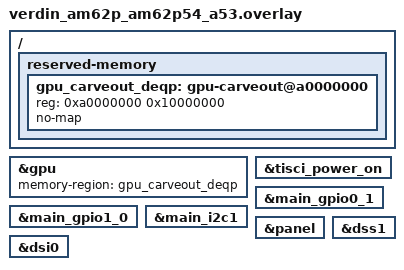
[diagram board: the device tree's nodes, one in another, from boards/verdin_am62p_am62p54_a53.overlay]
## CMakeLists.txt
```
# SPDX-License-Identifier: Apache-2.0
# SPDX-FileCopyrightText: 2026 Signal Slot, Inc.
# dEQP-GLES2 on Zephyr: the conformance suite as a Zephyr image, EGL/GLES from
# YakoGL, shaders from the in-process compiler. See README.md. One sample for
# every board: the Zephyr board (-b) picks the GPU and its board side, the
# board's files are in boards/. The STM32MP257F-DK's A35 adds the board
# layer's stm32mp2/app.conf (below). The Raspberry Pi 4 (V3D) adds src/v3d_board.c
# (the V3D's EGL default display and the result record, one screen the lead
# photographs), the mailbox framebuffer, the HDMI console and the
# bounded-lifetime watchdog of the rpi4 board layer.
#   -DDEQP_SRC=<CTS copy with cts-yakogl-zephyr.patch applied>
#   -DDEQP_BUILD=<its stage-1 build (static libraries)>
# tools/cts/cts-build-zephyr.sh makes both.
cmake_minimum_required(VERSION 3.20.0)
get_filename_component(PVR_REPO "${CMAKE_CURRENT_SOURCE_DIR}/../../.." ABSOLUTE)
include("${CMAKE_CURRENT_SOURCE_DIR}/../common/yakogl_dir.cmake")
# The STM32MP257F-DK's A35 takes the board layer's own board files, as
# gc_fence, gc_clear and gl_test do: app.conf here (the Vivante driver,
# OP-TEE's watchdog, no hold), app.overlay through
# boards/stm32mp257f_dk_stm32mp257fxx_a35.overlay, and dEQP's own needs in
# boards/stm32mp257f_dk_stm32mp257fxx_a35.conf.
if(BOARD MATCHES "^stm32mp257f_dk")
  set(EXTRA_CONF_FILE "${PVR_REPO}/zephyr/lib/board/stm32mp2/app.conf" ${EXTRA_CONF_FILE})
endif()
find_package(Zephyr REQUIRED HINTS $ENV{ZEPHYR_BASE})
project(deqp_zephyr)
set(PVR_SAMPLES "${CMAKE_CURRENT_SOURCE_DIR}/..")

foreach(v DEQP_SRC DEQP_BUILD)
  if(NOT ${v})
    message(FATAL_ERROR "deqp: set -D${v}=...")
  endif()
endforeach()

if(NOT CONFIG_YAKOGL_GPU_V3D)
  include("${PVR_SAMPLES}/common/sample.cmake")
endif()
# STM32MP257F-DK: the board layer (driver/zephyr/lib/board/stm32mp2) powers
# the GPU, arms OP-TEE's watchdog and ends the run (src/main.cpp:
# board_finish), with the yk-record line and PSCI SYSTEM_RESET into ST's Linux.
if(CONFIG_YAKOGL_STM32MP2 AND NOT CONFIG_YAKOGL_BOARD_STM32MP2)
  message(FATAL_ERROR "deqp: CONFIG_YAKOGL_BOARD is off (boards/stm32mp257f_dk_stm32mp257fxx_a35.conf turns it on)")
endif()

# Which dEQP package: gles2 (default) or gles3, against a stage 1 built with
# the same MODULE (tools/cts/cts-build-zephyr.sh). A gles3 image must let the
# library report ES 3.0: CONFIG_DEQP_REPORT_ES2=n and CONFIG_YAKOGL_REPORT_ES2=n
# (the latter is default y, so dropping the select alone still reports ES 2.0).
# dEQP-GLES3 on an ES 2.0 context is not supported.
if(NOT DEQP_MODULE)
  set(DEQP_MODULE gles2)
endif()
if(NOT DEQP_MODULE MATCHES "^gles[23]$")
  message(FATAL_ERROR "deqp: DEQP_MODULE must be gles2 or gles3, not ${DEQP_MODULE}")
endif()
if(DEQP_MODULE STREQUAL "gles3" AND CONFIG_DEQP_REPORT_ES2)
  message(FATAL_ERROR "deqp: DEQP_MODULE=gles3 needs CONFIG_DEQP_REPORT_ES2=n")
endif()
if(DEQP_MODULE STREQUAL "gles3" AND CONFIG_YAKOGL_REPORT_ES2)
  # DEQP_REPORT_ES2=n drops the select only; the library's default is y
  message(FATAL_ERROR "deqp: DEQP_MODULE=gles3 needs CONFIG_YAKOGL_REPORT_ES2=n too (the context must report ES 3.0)")
endif()
string(SUBSTRING "${DEQP_MODULE}" 4 1 _deqp_ver)

# the test data, embedded
set(_data_c "${CMAKE_CURRENT_BINARY_DIR}/deqp_data.c")
add_custom_command(OUTPUT "${_data_c}"
  COMMAND python3 "${CMAKE_CURRENT_SOURCE_DIR}/tools/embed_data.py"
          "${DEQP_BUILD}/modules/${DEQP_MODULE}/${DEQP_MODULE}" ${DEQP_MODULE} "${_data_c}"
  DEPENDS "${CMAKE_CURRENT_SOURCE_DIR}/tools/embed_data.py"
  COMMENT "embedding the dEQP ${DEQP_MODULE} test data")

target_sources(app PRIVATE src/main.cpp src/deqp_archive.cpp src/deqp_log.c src/deqp_stubs.c "${_data_c}"
  # the package registration lives in the executable's own entry file, not in
  # any library: without it the image has the tests but no package to run
  ${DEQP_SRC}/modules/${DEQP_MODULE}/tes${_deqp_ver}TestPackageEntry.cpp)
# The SNVS tally, on a board with yakogl_gc_board (the Verdin iMX8M Plus).
target_sources_ifdef(CONFIG_GC_COMMON_RESULT_SNVS app PRIVATE src/deqp_snvs.c)
target_include_directories(app PRIVATE src
  ${DEQP_SRC}/framework/common ${DEQP_SRC}/framework/qphelper
  ${DEQP_SRC}/framework/delibs/debase ${DEQP_SRC}/framework/delibs/decpp
  ${DEQP_SRC}/framework/delibs/depool ${DEQP_SRC}/framework/delibs/dethread
  ${DEQP_SRC}/framework/delibs/deutil ${DEQP_SRC}/framework/delibs/destream
  ${DEQP_SRC}/framework/referencerenderer ${DEQP_SRC}/framework/opengl
  ${DEQP_SRC}/framework/opengl/wrapper ${DEQP_SRC}/framework/egl
  ${DEQP_SRC}/framework/egl/wrapper ${DEQP_SRC}/modules/${DEQP_MODULE}
  ${DEQP_SRC}/modules/glshared ${DEQP_SRC}/framework/opengl/simplereference)
target_compile_definitions(app PRIVATE DE_OS=DE_OS_UNIX DE_CPU=DE_CPU_ARM_64
  DE_COMPILER=DE_COMPILER_GCC DE_PTR_SIZE=8)

# Raspberry Pi 4 (V3D 4.2): docs/online-shaderc/v3d-backend.md, "M8".
if(CONFIG_YAKOGL_GPU_V3D)
  execute_process(COMMAND git -C "${PVR_REPO}" describe --always --dirty
                  OUTPUT_VARIABLE V3D_BUILD OUTPUT_STRIP_TRAILING_WHITESPACE
                  RESULT_VARIABLE describe_rc)
  if(NOT describe_rc EQUAL 0 OR V3D_BUILD STREQUAL "")
    set(V3D_BUILD "unknown")
  endif()
  set(V3D_BOARD "${PVR_REPO}/zephyr/lib/board/rpi4")
  target_sources(app PRIVATE src/v3d_board.c "${V3D_BOARD}/rpi_mbox.c" "${V3D_BOARD}/fbcon.c")
  # The bounded-lifetime watchdog, on by default: every board image carries it.
  # Off only for a QEMU smoke run of the record (QEMU's raspi4b resets as soon
  # as the watchdog is armed).
  option(V3D_RPI_WDOG "the PM watchdog that bounds the image's lifetime" ON)
  if(V3D_RPI_WDOG)
    target_sources(app PRIVATE "${V3D_BOARD}/rpi_wdog.c")
  else()
    message(WARNING "deqp: built WITHOUT the watchdog (V3D_RPI_WDOG=OFF): QEMU only, never the board")
    target_compile_definitions(app PRIVATE V3D_NO_RPI_WDOG)
  endif()
  # The whole QPA to the UART (V3D_DEQP_QPA_UART): --wrap=fdevopen puts a tee
  # in front of the log stream, the one fdevopen call in the image
  # (deqp_log.c's fopen wrapper); Zephyr's own streams are static.
  # --wrap=qpTestLog_createFileLog turns the images and shader sources back on
  # (the command line turns them off).
  if(CONFIG_V3D_DEQP_QPA_UART)
    target_sources(app PRIVATE src/qpa_uart.c)
    zephyr_link_libraries(-Wl,--wrap=fdevopen -Wl,--wrap=qpTestLog_createFileLog)
  endif()
  target_compile_definitions(app PRIVATE
    V3D_BUILD="${V3D_BUILD}"
    # rpi_wdog.c: the image's whole lifetime, run and photo together
    RPI_WDOG_HOLD_S=${CONFIG_V3D_DEQP_LIFETIME_S})
  target_include_directories(app PRIVATE
    "${PVR_REPO}/zephyr/lib/board/common"    # sample_glue.h (the declaration only), gc_font8x16.h
    "${V3D_BOARD}"
    "${YAKOGL_DIR}/src/osal"                 # struct osal_zephyr_v3d_init
    "${PVR_REPO}/src/v3d")                   # struct v3d_clock_ops (v3d.h)
endif()

# PowerVR: the backend's option numbers (pvr/pvr_backend.h) for the A/B switches
if(CONFIG_YAKOGL_GPU_POWERVR)
  target_include_directories(app PRIVATE "${YAKOGL_DIR}/src")
endif()

# The stage-1 archives, in dependency order inside one group.
set(_libs
  modules/${DEQP_MODULE}/libdeqp-${DEQP_MODULE}-package.a
  modules/${DEQP_MODULE}/functional/libdeqp-${DEQP_MODULE}-functional.a
  modules/${DEQP_MODULE}/accuracy/libdeqp-${DEQP_MODULE}-accuracy.a
  modules/${DEQP_MODULE}/performance/libdeqp-${DEQP_MODULE}-performance.a
  modules/${DEQP_MODULE}/stress/libdeqp-${DEQP_MODULE}-stress.a
  modules/glshared/libdeqp-gl-shared.a
  framework/opengl/simplereference/libglutil-sglr.a
  framework/opengl/libglutil.a
  framework/opengl/wrapper/libglwrapper.a
  framework/egl/libeglutil.a
  framework/egl/wrapper/libeglwrapper.a
  framework/platform/libtcutil-platform.a
  framework/common/libtcutil.a
  framework/referencerenderer/libreferencerenderer.a
  framework/randomshaders/librandomshaders.a
  framework/qphelper/libqphelper.a
  framework/xexml/libxexml.a
  framework/delibs/decpp/libdecpp.a
  framework/delibs/deutil/libdeutil.a
  framework/delibs/dethread/libdethread.a
  framework/delibs/depool/libdepool.a
  framework/delibs/debase/libdebase.a
  external/jsoncpp/src/src/lib_json/libjsoncpp.a
  external/libpng/libpng.a
  external/zlib/libz.a)
set(_abs)
foreach(l ${_libs})
  list(APPEND _abs "${DEQP_BUILD}/${l}")
endforeach()
zephyr_link_libraries(-Wl,--start-group ${_abs} -Wl,--end-group -Wl,--wrap=fopen)
if(CONFIG_YAKOGL_GPU_V3D)
  # --wrap=eglGetDisplay and eglGetPlatformDisplay: v3d_board.c gives dEQP's
  # EGL_DEFAULT_DISPLAY the V3D OSAL's init argument (the board's V3D clock
  # switch). --wrap=glGetShaderInfoLog and glGetProgramInfoLog, with
  # glGetShaderiv and glGetProgramiv for their status: v3d_board.c keeps the
  # first line of a failed build's log for the record.
  zephyr_link_libraries(-Wl,--wrap=eglGetDisplay -Wl,--wrap=eglGetPlatformDisplay
    -Wl,--wrap=glGetShaderInfoLog -Wl,--wrap=glGetProgramInfoLog
    -Wl,--wrap=glGetShaderiv -Wl,--wrap=glGetProgramiv)
endif()
```

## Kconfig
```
# SPDX-License-Identifier: Apache-2.0
# SPDX-FileCopyrightText: 2026 Signal Slot, Inc.
menu "deqp"
config DEQP_CASE
	string "dEQP case filter (--deqp-case)"
	default "dEQP-GLES2.info.*"
config DEQP_CASE_TABLE
	string "Case filters a run-time selector can pick (';'-separated)"
	default ""
	help
	  On a board with the SNVS record (CONFIG_GC_COMMON_RESULT_SNVS), the
	  reader can write a selector before the jump (gc_result.h): index i
	  runs the i-th filter of this list instead of DEQP_CASE, so one image
	  serves many groups or single cases. An empty table, no selector, or
	  an index past the end runs DEQP_CASE.

config DEQP_REPORT_ES2
	bool "YakoGL reports OpenGL ES 2.0 (the dEQP-GLES2 image)"
	default y
	select YAKOGL_REPORT_ES2
	help
	  dEQP-GLES2 applies the rules of the version the context reports:
	  a context reporting ES 3.0 makes an NPOT texture with REPEAT
	  complete and a transposed glUniformMatrix legal, so the GLES2
	  module judges ES 3.0 behaviour. Every other GLES2 run (the Linux
	  pair, check.sh's row) uses report-es2; this is the same for the
	  Zephyr image. A dEQP-GLES3 image says n here AND sets
	  YAKOGL_REPORT_ES2=n (n here only drops the select; the library's
	  default stays y): tools/cts/am62p-deqp-images.sh passes both.
config DEQP_GL_CONFIG_NAME
	string "dEQP render config name (--deqp-gl-config-name), empty = not passed"
	default "$(DEQP_GL_CONFIG_NAME)"
	help
	  Passed to dEQP as --deqp-gl-config-name=<name> when not empty, for
	  example "rgba8888d24s8ms4" to run on YakoGL's 4x multisampled EGL
	  config (the pbuffer is created on it). Empty leaves dEQP's default,
	  which picks the single-sampled config; dEQP-GLES2.functional.
	  multisample.* then reports NotSupported ("No multisample buffers").
	  The default is the environment variable DEQP_GL_CONFIG_NAME (empty
	  when unset), for a direct west build. tools/cts/am62p-deqp-images.sh
	  does not read it: it passes the name explicitly, empty for every row
	  but one marked "(with DEQP_GL_CONFIG_NAME=<name>)", which is how
	  tools/cts/am62p-ms4-tree.txt builds the multisample image.
config DEQP_SURFACE_SIZE
	int "pbuffer width and height"
	default 256
config DEQP_TEST_KNOBS
	bool
	default y
	select YAKOGL_TEST_KNOBS
	help
	  dEQP is a test image: it builds the library with its test knobs
	  (CONFIG_YAKOGL_TEST_KNOBS). It sets none of them, so each stays at
	  the library's default.

config DEQP_ECHO_QPA
	bool "Echo the whole test log (QPA) to the console, shader sources and images included"
	default n
	help
	  A measurement image: every line of dEQP's log goes to the console
	  as "qpa: <line>" ("qpa+ " continues a line longer than 511 bytes),
	  and the log carries the shader sources and the result, reference
	  and error-mask images. tools/cts/qpa-from-uart.py rebuilds the .qpa
	  from a captured console, for tools/cts/cts-images.py. For a short
	  case filter only: the images take seconds each at the console's
	  baud rate. Used first to read the source dEQP generated on the
	  board for a case whose host source differs
	  (random.texture.vertex.41, 2026-09-25). The V3D image has its own
	  raw tee (CONFIG_V3D_DEQP_QPA_UART, the Pi 4).

config DEQP_PVR_NATIVE_CUBE
	int "PowerVR: the native cube (pvr_native_cube): -1 the library's default, 0 off, 1 on"
	depends on YAKOGL_GPU_POWERVR
	range -1 1
	default -1
	help
	  Passed to pvr_set_native_cube before the run when it is 0 or 1; -1
	  leaves the library's default (on since step C). Read when a shader
	  compiles: 0 makes the online compiler sample a samplerCube as the
	  stacked image again. One image per arm is the A/B of a cube case.

config DEQP_PVR_NATIVE_ARRAY
	int "PowerVR: the native 2D array (pvr_native_array): -1 the library's default, 0 off, 1 on"
	depends on YAKOGL_GPU_POWERVR
	range -1 1
	default -1
	help
	  Passed to pvr_set_native_array before the run when it is 0 or 1;
	  -1 leaves the library's default (off until a board run says
	  otherwise, docs/es3/pvr-2darray.md). Read when a shader compiles:
	  1 makes the online compiler sample a sampler2DArray by layer
	  address (smp tao) over a twiddled layer-major copy instead of the
	  stacked image (texture.filtering.2d_array, texture.shadow.2d_array,
	  texture.vertex.2d_array, the sampler2darray texture_functions).
	  One image per arm is the A/B of an array case.

config DEQP_PVR_NATIVE_3D
	int "PowerVR: the native 3D texture (pvr_native_3d): -1 the library's default, 0 off, 1 on"
	depends on YAKOGL_GPU_POWERVR
	range -1 1
	default -1
	help
	  Passed to pvr_set_native_3d before the run when it is 0 or 1; -1
	  leaves the library's default (off until a board run says
	  otherwise, docs/notes/pvr-3d-native.md). Read when a shader
	  compiles: 1 makes the online compiler sample a sampler3D as the
	  TPU's own 3D texture (smp 3d over a twiddled TEXTYPE_3D copy), with
	  its mip levels and wrap modes, instead of the grid of slices
	  (texture.mipmap.3d, texture.filtering.3d). One image per arm is the
	  A/B of a 3D case.

config DEQP_PROBE_POINTS
	string "The 0x4000 probe's five points, GL coordinates (\"x,y;x,y;...\"), empty = the centre and quarters"
	default ""
	depends on GC_COMMON_RESULT_SNVS
	help
	  Selector GC_RESULT_DEQP_SEL_PROBE (gc_result.h) reads five pixels of
	  the first failing case's picture. By default they are the centre and
	  the four quarter points of the CONFIG_DEQP_SURFACE_SIZE square; this
	  names them instead, in GL window coordinates (rows bottom-up) of
	  whatever framebuffer is bound when the result is logged. A missing
	  point keeps its default.

config DEQP_SNVS_ADDRESS
	bool "The kind-9 record's w3 carries the target's address bits and the lost work"
	depends on GC_COMMON_RESULT_SNVS && YAKOGL_GPU_VIVANTE
	help
	  For an address A/B (CONFIG_YAKOGL_GC_ALLOC_PAGE_ALIGN x
	  CONFIG_YAKOGL_GC_POOL_NO_REUSE): w3 becomes the default target's GPU
	  address, low 12 bits, << 20 | lost GPU work (4 bits) << 16 | GPU
	  resets (4 bits) << 12 | fence timeouts (4 bits) << 8 | what the
	  no-reuse pool leaked, in MiB (8 bits); each field saturates. Off
	  (the default), w3 carries the first failing case's name check and
	  index with the counters (gc_result.h), which is what every run
	  should be read by.
endmenu
menu "deqp on the Raspberry Pi 4 (V3D)"
	depends on YAKOGL_GPU_V3D
config V3D_DEQP_LIFETIME_S
	int "Seconds from boot to the watchdog reset (run and photo)"
	default 240
	help
	  The PM watchdog (driver/zephyr/lib/board/rpi4/rpi_wdog.c) is fed until this many
	  seconds after boot, and resets the board at most 10 s later. The case
	  list must finish inside it with V3D_DEQP_PHOTO_S to spare; a list that
	  does not is split over more images (docs/online-shaderc/v3d-backend.md,
	  "M8").
config V3D_DEQP_PHOTO_S
	int "Seconds the record stays on screen before the reset, at least"
	default 30
	help
	  At V3D_DEQP_LIFETIME_S minus this, a run that has not finished prints
	  the record it has so far, marked INCOMPLETE, and the screen stops
	  scrolling, so there is always a record to photograph.
config V3D_DEQP_QPA_UART
	bool "Copy dEQP's whole test log (QPA) to the UART"
	default n
	help
	  The deqp sample's log stream keeps only one line per case. With this
	  on, every character dEQP writes to its QPA log also goes to the UART:
	  the shader sources, the values, the result, reference and error-mask
	  images (the deqp sample's command line turns images and shader
	  sources off; this option turns them back on). The images make it slow (the UART is 115200 baud), so it is
	  meant for a filter of a few cases, where one case's pixels decide a
	  question. Off for every sweep image.
endmenu
rsource "../common/Kconfig"
source "Kconfig.zephyr"
```

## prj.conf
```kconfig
# SPDX-License-Identifier: Apache-2.0
# SPDX-FileCopyrightText: 2026 Signal Slot, Inc.
CONFIG_YAKOGL=y
# dEQP compiles the shaders it generates at run time: the in-process compiler.
CONFIG_YAKOGL_SHADERC_ONLINE=y
CONFIG_LOG=y
CONFIG_LOG_MODE_MINIMAL=y
CONFIG_FPU=y
CONFIG_CACHE_MANAGEMENT=y
# dEQP's delibs over Zephyr's POSIX layer, and a full C++ runtime.
CONFIG_POSIX_API=y
CONFIG_POSIX_THREADS=y
CONFIG_CPP=y
CONFIG_STD_CPP17=y
CONFIG_REQUIRES_FULL_LIBCPP=y
CONFIG_CPP_EXCEPTIONS=y
CONFIG_CPP_RTTI=y
# dEQP allocates freely; the compiler needs a deep stack (256 KiB floor).
CONFIG_COMMON_LIBC_MALLOC_ARENA_SIZE=67108864
CONFIG_MAIN_STACK_SIZE=1048576
CONFIG_STACK_SENTINEL=y
CONFIG_ENFORCE_ZEPHYR_STDINT=n
```

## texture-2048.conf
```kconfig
# SPDX-License-Identifier: Apache-2.0
# SPDX-FileCopyrightText: 2026 Signal Slot, Inc.
# The Pi 4 image that runs the seven dEQP-GLES2 texture.size.2d.2048x2048_*
# cases (image T5 of tools/cts/pi4-full-tree.txt). Build it with
#
#   west build ... driver/samples/zephyr/deqp -b rpi_4b -- -DEXTRA_CONF_FILE=texture-2048.conf ...
#
# A 2048x2048 RGBA8 texture tiles to about 16.8 MiB, its mip chain to
# 22,376,448 bytes: past boards/rpi_4b.conf's 16 MiB of kept tiled copies and past
# the per-job texture arena (8 MiB), so without this every such draw is
# refused ("a texture larger than the tiled-copy budget"). Sweep 28 ran T5
# with these two values and measured a high-water of 16,781,312 bytes of
# copies and 56,786,688 bytes of the carve-out; sweep 29 built T5 without
# them and failed five of the seven. Only this image needs them, so they
# stay out of the board file: every other image keeps the 48 MiB carve-out it
# was measured with.
CONFIG_YAKOGL_V3D_CARVEOUT_BYTES=67108864
CONFIG_YAKOGL_V3D_TILED_COPIES_BYTES=25165824
```

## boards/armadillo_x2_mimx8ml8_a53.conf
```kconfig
# SPDX-License-Identifier: Apache-2.0
# SPDX-FileCopyrightText: 2026 Signal Slot, Inc.
# Armadillo-X2 (A53), kexec'd out of Armadillo Base OS by tools/board.sh x2 on the
# crash route (crashkernel=256M@0x60000000). The same SoC and GPU as the Verdin
# (verdin_imx8mp_mimx8ml8_a53.conf is the template): the GC7000UL through YakoGL's
# Vivante back end, the GIC EOI fix, the interrupt guard, WDOG1 armed and fed for a
# BOUNDED 600 s (one dEQP group; then the watchdog resets the board back into
# Linux), and the SNVS result record. What differs:
#  - the console is UART2 (the board.sh console, BOARD_UART, the board's chosen
#    zephyr,console): the names of the failing cases come from it
#    (tools/cts/deqp-uart-tally.py);
#  - the record is LPGPR1..3 and no w3 (CONFIG_GC_COMMON_RESULT_SNVS_KEEP_LPGPR0,
#    the board's Kconfig.defconfig: LPGPR0 is U-Boot's boot count; gc_result.h),
#    so the failing names of a table row come from DEQP_FAILS pages of four (see
#    driver/tools/kexec-zephyr/README.md, "The Armadillo-X2");
#  - no display: dEQP renders offscreen, and the board's LCDIF3 adopt node is left
#    to Linux (the display driver would only bring the board layer's panel path in).
CONFIG_YAKOGL_DRV_GPU_PVR=n
CONFIG_YAKOGL_DRV_GPU_VIVANTE=y
CONFIG_YAKOGL_GPU_VIVANTE=y
CONFIG_YAKOGL_DRV_DISPLAY_IMX8MP=n

CONFIG_YAKOGL_GC_BOARD=y
# The image arms WDOG1 itself and feeds it from its own 1 s timer for 600 s;
# tools/board.sh refuses an image without its "gc_wdog_arm: armed" line.
CONFIG_GC_BOARD_WDOG_SELF_ARM=y
CONFIG_GC_BOARD_WDOG_SECONDS=600
CONFIG_GC_COMMON_PANEL_CONSOLE=n
# The board's Kconfig.defconfig defaults it to y already; said here because
# the tree's record decoding relies on it.
CONFIG_GC_COMMON_RESULT_SNVS_KEEP_LPGPR0=y
# sample_glue.c brings the reset-at-once fatal handler with YAKOGL_SAMPLE_REBOOT.
CONFIG_GC_SAMPLE_FATAL_HANDLER=n
CONFIG_UART_CONSOLE=y

# Done: reset through PSCI back into Linux, after a short hold.
CONFIG_YAKOGL_SAMPLE_HOLD_SECONDS=5
CONFIG_YAKOGL_SAMPLE_REBOOT=y
CONFIG_REBOOT=y
CONFIG_PM_CPU_OPS=y
CONFIG_PM_CPU_OPS_PSCI=y

# dEQP's own heap, the Verdin's 160 MiB and for the same reason (the
# texture.size 2048 cases, see its conf). The image's RAM is the 256 MiB at
# 0x60000000 (a53_ddr_section): ~200 MiB with this heap, so it fits the crash
# window 0x60000000..0x70000000. The GPU carveout (128 MiB at 0x80000000) is
# outside it.
CONFIG_COMMON_LIBC_MALLOC_ARENA_SIZE=167772160

# Kernel virtual address space: the image plus the GPU carveout map and the
# device blocks. The default 256 MiB of VM from 0x60000000 leaves too little
# beside a 200 MiB image (the Verdin's carveout map failed, 4f40f622); 512 MiB
# as the Verdin and the AM62P.
CONFIG_KERNEL_VM_SIZE=0x20000000
```

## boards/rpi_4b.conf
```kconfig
# SPDX-License-Identifier: Apache-2.0
# SPDX-FileCopyrightText: 2026 Signal Slot, Inc.
# Raspberry Pi 4 (V3D 4.2): YakoGL on the V3D with the in-process compiler (the
# V3D's only shader back end), reporting OpenGL ES 2.0: dEQP-GLES2 applies ES
# 2.0 rules only to a context that says ES 2.0 (DEQP_REPORT_ES2). A gles3
# image passes -DCONFIG_DEQP_REPORT_ES2=n -DCONFIG_YAKOGL_REPORT_ES2=n
# (tools/cts/pi4-deqp-images.sh, DEQP_MODULE=gles3 does).
CONFIG_YAKOGL_GPU_V3D=y
CONFIG_YAKOGL_V3D_CARVEOUT_BYTES=50331648
# Tiled texture copies kept across jobs. The default 8 MiB is 16 KiB short of
# a 512x512 cube's mip chain at 4 bytes a texel (texture.size.cube). The
# 2048x2048 image (T5) adds texture-2048.conf: 24 MiB with a 64 MiB
# carve-out (-DEXTRA_CONF_FILE=texture-2048.conf).
CONFIG_YAKOGL_V3D_TILED_COPIES_BYTES=16777216

# The console is the HDMI framebuffer (driver/zephyr/lib/board/rpi4/fbcon.c).
# The mini UART stays on as well, and dEQP's own stdout goes only there.
CONFIG_PRINTK=y
CONFIG_FPU_SHARING=y

# Address space: the image (256 MiB of RAM, the overlay), the carve-out's
# non-cacheable alias (48 MiB), the 3.6 MiB framebuffer and the device blocks.
CONFIG_MAX_XLAT_TABLES=128
CONFIG_KERNEL_VM_SIZE=0x20000000
```

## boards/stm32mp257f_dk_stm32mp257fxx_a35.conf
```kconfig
# SPDX-License-Identifier: Apache-2.0
# SPDX-FileCopyrightText: 2026 Signal Slot, Inc.
# STM32MP257F-DK, Cortex-A35 (Vivante GCNanoUltra31, 0x8000/0x6205; #1281),
# started by its own U-Boot through tools/board-stm32mp2.sh. The board layer's
# app.conf (the Vivante driver, OP-TEE's watchdog, no hold) is added by
# CMakeLists.txt, as for gl_test; this is what dEQP needs beyond it.
#
# The board layer (yakogl_board.h, board_stm32mp2.c): the GPU powered before
# main (gc_power_mp2.c), OP-TEE's watchdog armed ("gc_wdog_arm: armed", which
# the runner requires) and fed, the yk-record line on USART2, and the end of
# the run: board_finish() (src/main.cpp) prints "deqp: PASS"/"FAIL" and resets
# through PSCI back into ST's Linux. A fatal error takes the board layer's
# handler (stm32mp2.c: PSCI reset), so YAKOGL_SAMPLE_REBOOT stays off: its
# handler in sample_glue.c would be a second k_sys_fatal_error_handler.
# The console is USART2: every case's "deqp: <StatusCode> <case>" line goes
# there (tools/cts/deqp-uart-tally.py reads it).
CONFIG_YAKOGL_BOARD=y
CONFIG_PRINTK=y
CONFIG_YAKOGL_SAMPLE_REBOOT=n

# The layer resets the board this long after boot whatever dEQP is doing:
# 600 s, one dEQP group, as the i.MX8MP's and the AM62P's bounded watchdog
# feed. tools/board-stm32mp2.sh waits RUN_BOUND (default 120 s) for the end
# line: run it with RUN_BOUND=600 or more (README.md).
CONFIG_YAKOGL_STM32MP2_LIFETIME_S=600

# dEQP's own heap: 128 MiB, the dk-image-budget study's pick. The study measured
# the full-tree image on the i.MX8MP build (same stage 1, same 29-row table):
# the footprint is 49.2%, 74.2% and 86.7% of the runner's 256 MiB load window
# (0xa0000000..0xb0000000, tools/board-stm32mp2.sh) at 64, 128 and 160 MiB; the
# file is 10,641,008 bytes in all three, which fits bootfs. 64 MiB fails the
# mipmap cases with GL_OUT_OF_MEMORY (why the Verdin uses 160 MiB); 128 MiB
# keeps 34+ MB more of the window spare than 160 MiB. The GPU carve-out (64 MiB
# at 0xfa800000) is outside the window, and as on the i.MX8MP (64 MiB too) the
# 2048x2048 mipmap uploads may still end in GL_OUT_OF_MEMORY. These figures
# are the proxy's; the DK image's own is not measured here.
CONFIG_COMMON_LIBC_MALLOC_ARENA_SIZE=134217728

# Kernel virtual address space: the image plus the 64 MiB carve-out map and
# the device blocks need VM room above the image RAM (the Verdin's carve-out
# map failed with the default 256 MiB, 4f40f622). The DK's 36-bit VA has more
# room, but the pattern is kept: 512 MiB as the Verdin, the Armadillo-X2 and
# the AM62P. No devicetree region is identity-mapped in 0xa0000000..0xc0000000
# (DDR only).
CONFIG_KERNEL_VM_SIZE=0x20000000
```

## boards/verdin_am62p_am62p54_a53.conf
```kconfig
# SPDX-License-Identifier: Apache-2.0
# SPDX-FileCopyrightText: 2026 Signal Slot, Inc.
# Verdin AM62P entered from U-Boot (tools/board.sh uboot-tftp) or from Torizon
# Linux with tools/kexec-zephyr: bring the DSI panel up with the display
# drivers (used by the panel modes), run the cases, keep the result for the
# camera, then reset back into Linux.
CONFIG_YAKOGL_DRV_GPU_PVR=y
CONFIG_YAKOGL_SAMPLE_HOLD_SECONDS=20
CONFIG_YAKOGL_SAMPLE_REBOOT=y
CONFIG_REBOOT=y
# The image arms the MAIN RTI0 watchdog itself (U-Boot starts none; on a kexec
# entry it is already running and is only fed): fed for 600 s (one dEQP group),
# then a hung image is reset by it. tools/board.sh refuses an AM62P image
# without this feeder's "rti_arm: armed" line; the inherited-watchdog feeder
# this replaced (SOC_AM62PX_A53_FEED_INHERITED_WDT) prints none, so every
# image built from this file was refused (2026-10-04, the baseline images).
CONFIG_SOC_AM62PX_A53_FEED_INHERITED_WDT=n
CONFIG_YAKOGL_AM62P_RTI_SELF_ARM=y
# The bound, for whichever feeder runs (common/Kconfig).
CONFIG_YAKOGL_AM62P_WDT_SECONDS=600

# Init order: mailbox 40 -> TISCI 45 -> TISCI power-on 46 -> GPIO 47 ->
# I2C 50 -> DSI 70 -> DSS 80 -> GPU 90 -> panel bridge 95.
CONFIG_MBOX=y
CONFIG_MBOX_TI_SECURE_PROXY=y
CONFIG_TISCI=y
CONFIG_TISCI_INIT_PRIORITY=45
CONFIG_GPIO_INIT_PRIORITY=47
CONFIG_YAKOGL_DRV_SN65DSI8X_SELF_START_INIT_PRIORITY=95

# Console on main_uart0 (Verdin UART_3, the X18 debug USB).
CONFIG_LOG_MODE_MINIMAL=y
# Early UART markers ('H', 'K') for boots that never reach the banner.
CONFIG_SOC_AM62PX_A53_BOOT_MARKER=y

# Address space: the image plus the 256 MiB GPU carve-out (the overlay) and the
# device blocks. At the default 256 MiB the carve-out's mapping failed at boot
# ("insufficient virtual address space (requested 268435456)", 1eda74e5).
CONFIG_MAX_XLAT_TABLES=128
CONFIG_KERNEL_VM_SIZE=0x20000000
```

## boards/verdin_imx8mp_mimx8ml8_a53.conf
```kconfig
# SPDX-License-Identifier: Apache-2.0
# SPDX-FileCopyrightText: 2026 Signal Slot, Inc.
# Verdin iMX8M Plus (A53) on a Mallow carrier, started by U-Boot (tools/board.sh
# uboot-tftp) or kexec'd out of Torizon on the crash route. The GC7000UL through
# YakoGL's Vivante back end, and the board support of yakogl_gc_board: the GIC
# EOI fix, the interrupt guard, WDOG1 armed and fed for a BOUNDED 600 s (one
# dEQP group; then the watchdog resets the board back into Linux), and the SNVS
# result record. The console is off by default (the Verdin UART_3, i.MX8MP UART3, on the Mallow
# debug header X11 is wired to a console bridge; tools/cts/imx8mp-console.conf,
# IMX8MP_CONSOLE=1, turns it on), so a run's result leaves the board in the
# SNVS DEQP record (gc_result.h), rewritten after every case (src/deqp_snvs.c).
CONFIG_YAKOGL_DRV_GPU_PVR=n
CONFIG_YAKOGL_DRV_GPU_VIVANTE=y
CONFIG_YAKOGL_GPU_VIVANTE=y

CONFIG_YAKOGL_GC_BOARD=y
# The image arms WDOG1 itself (U-Boot may leave it stopped; on a kexec entry
# the running one is re-timed) and feeds it from its own 1 s timer for 600 s
# (one dEQP group), as every U-Boot gl_test and glmark2 image of this board.
# tools/board.sh refuses an i.MX8MP image without its "gc_wdog_arm: armed"
# line; the timer feeder of an inherited WDOG1 this replaced
# (GC_SAMPLE_WDOG_TIMER_FEED) prints none (2026-10-04, the baseline image).
CONFIG_GC_BOARD_WDOG_SELF_ARM=y
CONFIG_GC_BOARD_WDOG_SECONDS=600
CONFIG_GC_COMMON_PANEL_CONSOLE=n
# sample_glue.c brings the reset-at-once fatal handler with YAKOGL_SAMPLE_REBOOT.
CONFIG_GC_SAMPLE_FATAL_HANDLER=n
CONFIG_UART_CONSOLE=n

# Done: reset through PSCI back into Linux, after a short hold.
CONFIG_YAKOGL_SAMPLE_HOLD_SECONDS=5
CONFIG_YAKOGL_SAMPLE_REBOOT=y
CONFIG_REBOOT=y
CONFIG_PM_CPU_OPS=y
CONFIG_PM_CPU_OPS_PSCI=y

# dEQP's own heap. texture.size.2d.2048x2048_l8_mipmap ended every full
# texture.size run (e51d057f): a non-Pass status and then the end of the
# process with no FAULT record, which is dEQP's answer to std::bad_alloc
# (tcuTestSessionExecutor: RESOURCE_ERROR and terminate-after). Correction
# (2026-09-25): a GL_OUT_OF_MEMORY ends the run too. glu::OutOfMemoryError
# is a tcu::ResourceError, whose isFatal() is true (tcuDefs.hpp), so the
# executor sets terminate-after for it as well. Nobody read which of the
# two ended e51d057f's run. At 4f40f622 the run still ends at
# 2d.2048x2048_l8_mipmap, with "Texture upload failed: glGetError()
# returned GL_OUT_OF_MEMORY" (the 32 MiB chain does not fit the 64 MiB
# carveout), and a 200 MiB heap ends it at the same case.
# The 64 MiB of prj.conf held the case's reference chain on top of what the
# 2048 cases before it left fragmented. The image uses ~108 MB of the
# 256 MiB a53_ddr_section at 0x60000000 with 64 MiB here (text 7.1, rodata
# 1.8, bss 30.7, noinit 68 incl. this arena, da80e725), so 160 MiB leaves
# ~50 MB spare. The GPU carveout (64 MiB at 0x58000000) is separate.
CONFIG_COMMON_LIBC_MALLOC_ARENA_SIZE=167772160

# Kernel virtual address space: the image plus the 64 MiB GPU carveout map
# (gc_render.c, k_mem_map_phys_bare) and the device blocks. With the 160 MiB
# heap above the image's RAM footprint is 200 MiB (0xc86b000, 4f40f622), and the
# default 256 MiB of VM from 0x60000000 leaves ~56 MiB: the carveout map
# failed and every image panicked before its first case (k_panic in
# k_mem_map_phys_bare, fault record ELR 0x60525d1c, 4f40f622). 512 MiB, as
# the AM62P's conf: fbo 648 / 0 / 63 in three boots with it.
CONFIG_KERNEL_VM_SIZE=0x20000000
```

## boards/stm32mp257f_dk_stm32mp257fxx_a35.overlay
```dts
/* SPDX-License-Identifier: Apache-2.0 */
/* SPDX-FileCopyrightText: 2026 Signal Slot, Inc. */
/* The STM32MP257F-DK's A35: the board layer's GPU node and carve-out (the
 * 64 MiB gpu-reserved area at 0xfa800000), as gc_fence, gc_clear and gl_test
 * take them. */
#include "../../../../zephyr/lib/board/stm32mp2/app.overlay"
```

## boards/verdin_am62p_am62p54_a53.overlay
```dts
/* SPDX-License-Identifier: Apache-2.0 */
/* SPDX-FileCopyrightText: 2026 Signal Slot, Inc. */
/*
 * Toradex Verdin AM62P (board definition). The board DTS has the GPU
 * node with its 64 MiB carveout and the display path wired but disabled
 * (the R5F owns the display in the platform). This stand-alone
 * application drives the panel itself, so it enables DSS1, DSI, the bridge
 * on I2C1, the GPIO banks and the TISCI power-on list.
 */

/* A 256 MiB GPU carveout instead of the board's 64 MiB one, as the Qt
 * firmware takes: dEQP's texture.size group uploads 2048x2048 textures with
 * their mip chains, and with 64 MiB the 2048x2048 L8 upload returned
 * GL_OUT_OF_MEMORY, which dEQP treats as a ResourceError that ABORTS the run
 * (AM62P, 2026-09-24: texture.* stopped after 445 cases). Linux reserves
 * nothing from 0xa0000000 up and the image is kexec'ed, so that DDR is ours;
 * the board's 64 MiB region stays reserved but unused. */
/ {
	reserved-memory {
		gpu_carveout_deqp: gpu-carveout@a0000000 {
			reg = <0xa0000000 0x10000000>;
			no-map;
		};
	};
};

&gpu {
	memory-region = <&gpu_carveout_deqp>;
};

&tisci_power_on {
	status = "okay";
};

&main_gpio0_1 {
	status = "okay";
};

&main_gpio1_0 {
	status = "okay";
};

&main_i2c1 {
	status = "okay";
};

&panel {
	status = "okay";
};

&dss1 {
	status = "okay";
};

&dsi0 {
	status = "okay";
};
```

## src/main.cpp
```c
/* SPDX-License-Identifier: Apache-2.0 */
/* SPDX-FileCopyrightText: 2026 Signal Slot, Inc. */
/*
 * dEQP on Zephyr: the tcu::App main loop of framework/platform/tcuMain.cpp,
 * with the arguments built in (there is no command line), the test data from
 * a memory archive and the log turned into one result line per case
 * (deqp_log.c). EGL/GLES are YakoGL, linked in directly.
 */
#include "tcuApp.hpp"
#include "tcuCommandLine.hpp"
#include "tcuPlatform.hpp"
#include "tcuTestLog.hpp"
#include "tcuTestPackage.hpp"
#include "deUniquePtr.hpp"
#include "deqp_archive.hpp"
#include "qpDebugOut.h"
#include <cstdarg>
#include <cstdio>
#include <cstring>
#include <exception>

extern "C" {
#include <zephyr/kernel.h>
#include <zephyr/sys/printk.h>
#include <zephyr/sys/util.h>
#include "sample_glue.h"
#ifdef CONFIG_YAKOGL_BOARD_STM32MP2
#include "yakogl_board.h"
#endif
#ifdef CONFIG_YAKOGL_GPU_POWERVR
void pvr_set_native_cube(int on);
extern int pvr_native_cube;   /* src/shaderc/mod.rs: the switch itself */
void pvr_set_native_array(int on);
extern int pvr_native_array;  /* src/shaderc/mod.rs: the 2D-array switch */
void pvr_set_native_3d(int on);
extern int pvr_native_3d;     /* src/shaderc/mod.rs: the 3D-texture switch */
#endif
void deqp_log_summary(void);
}

tcu::Platform *createPlatform(void);

/*
 * dEQP ends a run it cannot continue with tcu::die() -> qpDiev(): it prints
 * the message with type MESSAGETYPE_ERROR, then calls exitProcess(). Its
 * non-Windows arm is fflush(NULL) and raise(SIGKILL). picolibc's tinystdio
 * fflush() does not accept NULL: it reads stream->flush (offset 0x18). So on
 * Zephyr a die() was a data abort at FAR 0x18, with no summary line
 * (AM62P, dEQP-GLES3.functional.lifetime.*, 2026-09-26: the group's init
 * fails TCU_CHECK(isOk()) on a program that asks for transform feedback).
 * raise() would not have ended anything either.
 *
 * This hook sees the fatal message before exitProcess() runs and ends the
 * image itself. It prints dEQP's message, a "deqp: fatal:" line and the
 * usual summary, then takes Zephyr's fatal path (k_panic). That is where
 * dEQP's own assertion failures already go on Zephyr (deAssertFail ->
 * abort()), and sample_glue.c's handler writes the FAULT record there and
 * resets. exitProcess() is never reached.
 *
 * MESSAGETYPE_ERROR is 1 in qpDebugOut.c's private enum (INFO 0, ERROR 1,
 * NONFATAL_ERROR 2). Only qpDief() and qpDiev() use it, and both call
 * exitProcess() next. Every other type is printed by dEQP as before.
 */
static bool deqp_fatal_redirect(int type, const char *format, va_list args)
{
    static const int message_type_error = 1;

    if (type != message_type_error)
        return true; /* dEQP prints it itself */
    printk("FATAL ERROR: ");
    vprintk(format, args);
    printk("\ndeqp: fatal: dEQP ended the run (die()); later cases did not run\n");
    deqp_log_summary();
    k_panic();
    return false; /* not reached */
}

#ifdef CONFIG_GC_COMMON_RESULT_SNVS
extern "C" int gc_result_selector(void);

/* The --deqp-case argument: DEQP_CASE, or the table entry the reader's
 * selector names (Kconfig DEQP_CASE_TABLE). */
static const char *case_argument(void)
{
    static char arg[2048]; /* a batch: comma-separated patterns */
    const char *table = CONFIG_DEQP_CASE_TABLE;
    int want = gc_result_selector();

    if (want >= 0)
        want &= 0xff; /* the rest names a page of failures (gc_result.h) */

    if (want >= 0) {
        for (int i = 0; *table; i++) {
            const char *end = strchr(table, ';');
            size_t n = end ? (size_t)(end - table) : strlen(table);

            if (i == want && n > 0 && n < sizeof(arg) - sizeof("--deqp-case=")) {
                snprintf(arg, sizeof(arg), "--deqp-case=%.*s", (int)n, table);
                printk("deqp: selector %d\n", want);
                return arg;
            }
            if (!end)
                break;
            table = end + 1;
        }
    }
    return "--deqp-case=" CONFIG_DEQP_CASE;
}
#endif

extern "C" int main(void)
{
#ifdef CONFIG_GC_COMMON_RESULT_SNVS
    const char *argv[] = {
        "deqp",
        case_argument(),
#else
    static const char *argv[] = {
        "deqp",
        "--deqp-case=" CONFIG_DEQP_CASE,
#endif
        "--deqp-surface-type=pbuffer",
        "--deqp-surface-width=" STRINGIFY(CONFIG_DEQP_SURFACE_SIZE),
        "--deqp-surface-height=" STRINGIFY(CONFIG_DEQP_SURFACE_SIZE),
        "--deqp-log-filename=deqp.qpa",
#ifdef CONFIG_DEQP_ECHO_QPA
        "--deqp-log-images=enable",
        "--deqp-log-shader-sources=enable",
#else
        "--deqp-log-images=disable",
        "--deqp-log-shader-sources=disable",
#endif
        "--deqp-watchdog=disable",
#ifdef CONFIG_DEQP_GL_CONFIG_NAME
        /* last, so an empty name drops it from argc below (dEQP rejects a
         * repeated option, and a config called "" does not exist) */
        "--deqp-gl-config-name=" CONFIG_DEQP_GL_CONFIG_NAME,
#endif
    };
    int rc = 0;

    qpRedirectOut(nullptr, deqp_fatal_redirect);
#ifdef CONFIG_GC_COMMON_RESULT_SNVS
    printk("deqp: case filter '%s'\n", argv[1] + sizeof("--deqp-case=") - 1);
#else
    printk("deqp: case filter '%s'\n", CONFIG_DEQP_CASE);
#endif
#ifdef CONFIG_YAKOGL_GPU_POWERVR
    /* the A/B switches: -1 leaves the library's default, and says so */
    if (CONFIG_DEQP_PVR_NATIVE_CUBE >= 0)
        pvr_set_native_cube(CONFIG_DEQP_PVR_NATIVE_CUBE);
    printk("deqp: pvr_native_cube=%d (CONFIG_DEQP_PVR_NATIVE_CUBE=%d%s)\n", pvr_native_cube,
           CONFIG_DEQP_PVR_NATIVE_CUBE, CONFIG_DEQP_PVR_NATIVE_CUBE >= 0 ? "" : ": the library's default");
    if (CONFIG_DEQP_PVR_NATIVE_ARRAY >= 0)
        pvr_set_native_array(CONFIG_DEQP_PVR_NATIVE_ARRAY);
    printk("deqp: pvr_native_array=%d (CONFIG_DEQP_PVR_NATIVE_ARRAY=%d%s)\n", pvr_native_array,
           CONFIG_DEQP_PVR_NATIVE_ARRAY, CONFIG_DEQP_PVR_NATIVE_ARRAY >= 0 ? "" : ": the library's default");
    if (CONFIG_DEQP_PVR_NATIVE_3D >= 0)
        pvr_set_native_3d(CONFIG_DEQP_PVR_NATIVE_3D);
    printk("deqp: pvr_native_3d=%d (CONFIG_DEQP_PVR_NATIVE_3D=%d%s)\n", pvr_native_3d,
           CONFIG_DEQP_PVR_NATIVE_3D, CONFIG_DEQP_PVR_NATIVE_3D >= 0 ? "" : ": the library's default");
#endif
    try
    {
        int argc = (int)(sizeof(argv) / sizeof(argv[0]));
#ifdef CONFIG_DEQP_GL_CONFIG_NAME
        if (sizeof(CONFIG_DEQP_GL_CONFIG_NAME) == 1)
            argc--;
#endif
        tcu::CommandLine cmdLine(argc, (char **)argv);
        MemArchive archive;
        tcu::TestLog log(cmdLine.getLogFileName(), cmdLine.getLogFlags());
        de::UniquePtr<tcu::Platform> platform(createPlatform());
        de::UniquePtr<tcu::App> app(new tcu::App(*platform, archive, log, cmdLine));

        while (app->iterate())
        {
        }
        const tcu::TestRunStatus &r = app->getResult();
        printk("deqp: done: %d passed, %d failed, %d not supported, %d warnings, complete=%d\n",
               r.numPassed, r.numFailed, r.numNotSupported, r.numWarnings, (int)r.isComplete);
        rc = (!r.isComplete || r.numFailed) ? -1 : 0;
    }
    catch (const std::exception &e)
    {
        printk("deqp: exception: %s\n", e.what());
        rc = -2;
    }
    deqp_log_summary();
#ifdef CONFIG_YAKOGL_BOARD_STM32MP2
    /* the STM32MP257F-DK: "deqp: PASS"/"FAIL", the yk-record line and PSCI
     * SYSTEM_RESET back into ST's Linux (board_stm32mp2.c) */
    board_finish("deqp", rc);
#else
    return pvr_sample_finish(rc);
#endif
}
```

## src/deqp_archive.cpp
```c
/* SPDX-License-Identifier: Apache-2.0 */
/* SPDX-FileCopyrightText: 2026 Signal Slot, Inc. */
/*
 * A tcu::Archive over the test data linked into the image: there is no file
 * system on the board, and the data (1.1 MB for GLES2) fits in RAM easily.
 */
#include "deqp_archive.hpp"
#include "deqp_data.h"
#include "tcuResource.hpp"
#include "tcuDefs.hpp"
#include <cstring>

namespace
{

class MemResource : public tcu::Resource
{
public:
    MemResource(const char *name, const uint8_t *bytes, uint32_t size)
        : tcu::Resource(name), m_bytes(bytes), m_size(size), m_pos(0)
    {
    }
    void read(uint8_t *dst, int numBytes)
    {
        if (numBytes < 0 || (uint32_t)numBytes > m_size - m_pos)
            throw tcu::ResourceError("read past the end of an embedded resource", getName().c_str(), __FILE__, __LINE__);
        memcpy(dst, m_bytes + m_pos, (size_t)numBytes);
        m_pos += (uint32_t)numBytes;
    }
    uint32_t getSize(void) const
    {
        return m_size;
    }
    uint32_t getPosition(void) const
    {
        return m_pos;
    }
    void setPosition(uint32_t position)
    {
        m_pos = position > m_size ? m_size : position;
    }

private:
    const uint8_t *m_bytes;
    uint32_t m_size;
    uint32_t m_pos;
};

} // namespace

tcu::Resource *MemArchive::getResource(const char *name) const
{
    size_t lo = 0, hi = deqp_num_files;

    while (lo < hi)
    {
        const size_t mid = (lo + hi) / 2;
        const int c      = strcmp(deqp_files[mid].name, name);

        if (c == 0)
            return new MemResource(name, deqp_files[mid].bytes, deqp_files[mid].size);
        if (c < 0)
            lo = mid + 1;
        else
            hi = mid;
    }
    throw tcu::ResourceError("no embedded resource", name, __FILE__, __LINE__);
}
```

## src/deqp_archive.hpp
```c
/* SPDX-License-Identifier: Apache-2.0 */
/* SPDX-FileCopyrightText: 2026 Signal Slot, Inc. */
#ifndef DEQP_ARCHIVE_HPP
#define DEQP_ARCHIVE_HPP
#include "tcuResource.hpp"
class MemArchive : public tcu::Archive
{
public:
    tcu::Resource *getResource(const char *name) const;
};
#endif
```

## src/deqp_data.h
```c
/* SPDX-License-Identifier: Apache-2.0 */
/* SPDX-FileCopyrightText: 2026 Signal Slot, Inc. */
#ifndef DEQP_DATA_H
#define DEQP_DATA_H
#include <stddef.h>
#include <stdint.h>
#ifdef __cplusplus
extern "C" {
#endif
/* The test data, embedded at build time (tools/embed_data.py), sorted by name. */
struct deqp_file {
	const char *name;
	const uint8_t *bytes;
	uint32_t size;
};
extern const struct deqp_file deqp_files[];
extern const size_t deqp_num_files;
#ifdef __cplusplus
}
#endif
#endif
```

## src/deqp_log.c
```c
/* SPDX-License-Identifier: Apache-2.0 */
/* SPDX-FileCopyrightText: 2026 Signal Slot, Inc. */
/*
 * dEQP writes its test log (QPA) with fopen(); the board has no file system.
 * --wrap=fopen hands dEQP a picolibc stream (fdevopen) for the log name, and
 * that stream never stores the log: it reads it line by line and turns each
 * case into one result line on the console,
 *
 *     deqp: <status> <case name>
 *
 * from "#beginTestCaseResult <name>" and the case's <Result StatusCode="..">.
 * A case that begins and never reaches a result (a crash, a hang the watchdog
 * ends) has no line, and the summary's count says so: absence is its own
 * outcome, never folded into pass or fail.
 */
#include <stdio.h>
#include <string.h>
#include <zephyr/sys/printk.h>

#define DEQP_LOG_NAME "deqp.qpa"

static char line[512];
static size_t len;
static char cur_case[256];
static unsigned int n_begun, n_result;

#ifdef CONFIG_GC_COMMON_RESULT_SNVS
/* deqp_snvs.c: the board keeps a running tally where a reset cannot lose it
 * (a status of NULL: a case began). Absent from the other boards' builds. */
void deqp_snvs_progress(const char *status, const char *name);
#endif

#ifdef CONFIG_DEQP_ECHO_QPA
/* 1 while the next piece continues a line longer than the buffer */
static int echo_cont;
#endif

static void take_line(void)
{
	static const char begin[] = "#beginTestCaseResult ";
	static const char result[] = "<Result StatusCode=\"";

	line[len] = 0;
#ifdef CONFIG_DEQP_ECHO_QPA
	/* "qpa: " starts a log line, "qpa+ " continues one the buffer split */
	printk("%s%s\n", echo_cont ? "qpa+ " : "qpa: ", line);
#endif
	if (strncmp(line, begin, sizeof(begin) - 1) == 0) {
		strncpy(cur_case, line + sizeof(begin) - 1, sizeof(cur_case) - 1);
		cur_case[sizeof(cur_case) - 1] = 0;
		n_begun++;
#ifdef CONFIG_GC_COMMON_RESULT_SNVS
		deqp_snvs_progress(NULL, cur_case);
#endif
		return;
	}
	/* The info group's answers (GL_VERSION, GL_VENDOR, ...) are the only
	 * text worth a console line: they say which version the image reports,
	 * and nothing else shows it on a board without a file system. */
	if (strncmp(cur_case, "dEQP-GLES", 9) == 0 && strstr(cur_case, ".info.") != NULL) {
		const char *t = strstr(line, "<Text>");
		const char *e = t ? strstr(t, "</Text>") : NULL;

		if (t && e) {
			printk("deqp:   %.*s\n", (int)(e - t - 6), t + 6);
		}
	}
	const char *r = strstr(line, result);

	if (r && cur_case[0]) {
		char status[32];
		size_t i = 0;

		r += sizeof(result) - 1;
		while (r[i] && r[i] != '"' && i < sizeof(status) - 1) {
			status[i] = r[i];
			i++;
		}
		status[i] = 0;
		printk("deqp: %s %s\n", status, cur_case);
		n_result++;
#ifdef CONFIG_GC_COMMON_RESULT_SNVS
		deqp_snvs_progress(status, cur_case);
#endif
		cur_case[0] = 0;
	}
}

static int qpa_put(char c, FILE *f)
{
	(void)f;
	if (c == '\n' || len == sizeof(line) - 1) {
		take_line();
		len = 0;
#ifdef CONFIG_DEQP_ECHO_QPA
		echo_cont = c != '\n';
#endif
		if (c == '\n')
			return (unsigned char)c;
	}
	line[len++] = c;
	return (unsigned char)c;
}

static int qpa_flush(FILE *f)
{
	(void)f;
	return 0;
}

FILE *__real_fopen(const char *path, const char *mode);
FILE *__wrap_fopen(const char *path, const char *mode)
{
	if (path && strcmp(path, DEQP_LOG_NAME) == 0)
		return fdevopen(qpa_put, NULL, qpa_flush);
	return __real_fopen(path, mode);
}

void deqp_log_summary(void)
{
	printk("deqp: summary: %u cases begun, %u with a result, %u without\n", n_begun, n_result,
	       n_begun - n_result);
}
```

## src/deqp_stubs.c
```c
/* SPDX-License-Identifier: Apache-2.0 */
/* SPDX-FileCopyrightText: 2026 Signal Slot, Inc. */
/*
 * What dEQP's framework references and a Zephyr image does not have: child
 * processes (tcu::CommandLine's subprocess execution modes, never selected
 * here) and three file-system calls. Each fails the way the real call fails
 * when the thing does not exist, so a path that reaches one reports an error
 * instead of misbehaving.
 */
#include <errno.h>
#include <stdbool.h>
#include <stddef.h>
#include <sys/types.h>
#include <sys/stat.h>
#include "deProcess.h"

deProcess *deProcess_create(void)
{
	return NULL;
}

void deProcess_destroy(deProcess *process)
{
	(void)process;
}

bool deProcess_start(deProcess *process, const char *commandLine, const char *workingDirectory)
{
	(void)process;
	(void)commandLine;
	(void)workingDirectory;
	return false;
}

bool deProcess_isRunning(deProcess *process)
{
	(void)process;
	return false;
}

int deProcess_getExitCode(const deProcess *process)
{
	(void)process;
	return -1;
}

char *getcwd(char *buf, size_t size)
{
	(void)buf;
	(void)size;
	errno = ENOSYS;
	return NULL;
}

int lstat(const char *path, struct stat *st)
{
	(void)path;
	(void)st;
	errno = ENOENT;
	return -1;
}

ssize_t readlink(const char *path, char *buf, size_t size)
{
	(void)path;
	(void)buf;
	(void)size;
	errno = ENOENT;
	return -1;
}
```

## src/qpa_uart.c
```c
/* SPDX-License-Identifier: Apache-2.0 */
/* SPDX-FileCopyrightText: 2026 Signal Slot, Inc. */
/*
 * CONFIG_V3D_DEQP_QPA_UART: dEQP's whole QPA log to the UART, for a filter
 * of a few cases whose pixels decide a question.
 *
 * The deqp sample's fopen wrapper (deqp_log.c) gives dEQP a picolibc stream
 * from fdevopen(qpa_put, ...), and qpa_put keeps one line per case. Linked
 * with --wrap=fdevopen, the stream's put function becomes a tee: each
 * character goes to the UART, then to qpa_put as before. deqp_log.c is not
 * changed. There is one such stream (deqp.qpa), opened once.
 *
 * The deqp sample's command line also says --deqp-log-images=disable and
 * --deqp-log-shader-sources=disable, which dEQP turns into the flags of
 * qpTestLog_createFileLog(). Linked with --wrap=qpTestLog_createFileLog,
 * this file clears those two flags, so the QPA carries the result, reference
 * and error-mask images and the shader sources: what a copy of it is for.
 */
#include <stdint.h>
#include <stdio.h>

/* v3d_board.c: a character to the UART only */
void v3d_board_uart_putc(char c);

FILE *__real_fdevopen(int (*put)(char, FILE *), int (*get)(FILE *), int (*flush)(FILE *));

static int (*inner_put)(char, FILE *);

static int tee_put(char c, FILE *f)
{
	v3d_board_uart_putc(c);
	return inner_put ? inner_put(c, f) : (unsigned char)c;
}

FILE *__wrap_fdevopen(int (*put)(char, FILE *), int (*get)(FILE *), int (*flush)(FILE *))
{
	if (!put || inner_put)
		return __real_fdevopen(put, get, flush); /* not a log stream, or a second one */
	inner_put = put;
	return __real_fdevopen(tee_put, get, flush);
}

/* qpTestLog.h's qpTestLogFlag values: the two this image wants off */
#define QPA_EXCLUDE_IMAGES         (1u << 0)
#define QPA_EXCLUDE_SHADER_SOURCES (1u << 1)

typedef struct qpTestLog_s qpTestLog;
qpTestLog *__real_qpTestLog_createFileLog(const char *fileName, uint32_t flags);
qpTestLog *__wrap_qpTestLog_createFileLog(const char *fileName, uint32_t flags)
{
	return __real_qpTestLog_createFileLog(fileName,
					      flags & ~(QPA_EXCLUDE_IMAGES | QPA_EXCLUDE_SHADER_SOURCES));
}
```
